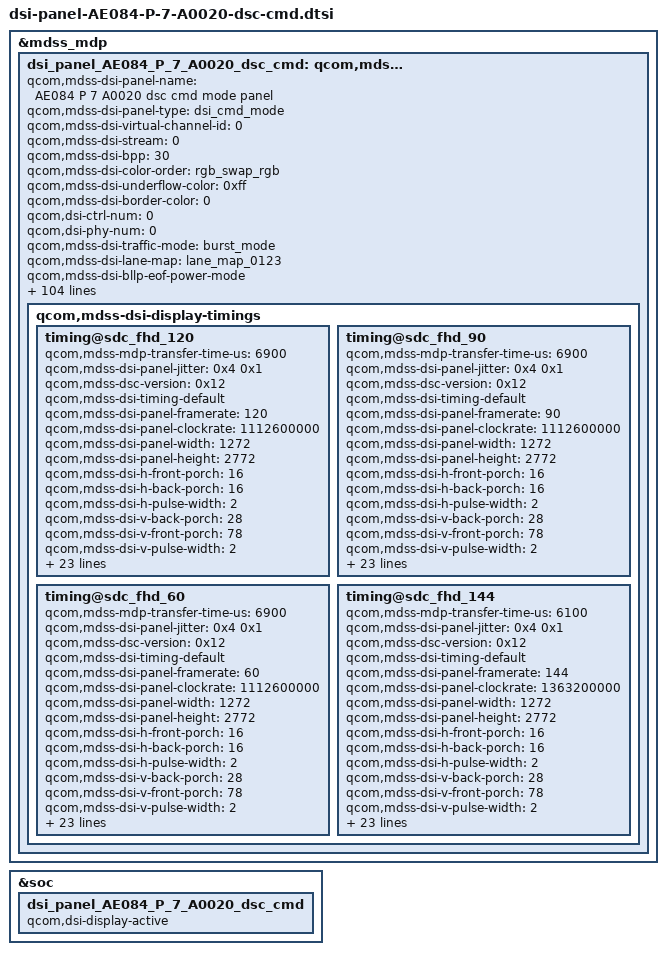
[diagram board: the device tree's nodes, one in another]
&mdss_mdp {
	dsi_panel_AE084_P_7_A0020_dsc_cmd: qcom,mdss_dsi_panel_AE084_P_7_A0020_dsc_cmd {
		qcom,mdss-dsi-panel-name = "AE084 P 7 A0020 dsc cmd mode panel";
		qcom,mdss-dsi-panel-type = "dsi_cmd_mode";
		qcom,mdss-dsi-virtual-channel-id = <0>;
		qcom,mdss-dsi-stream = <0>;
		qcom,mdss-dsi-bpp = <30>;
		qcom,mdss-dsi-color-order = "rgb_swap_rgb";
		qcom,mdss-dsi-underflow-color = <0xff>;
		qcom,mdss-dsi-border-color = <0>;
		qcom,dsi-ctrl-num = <0>;
		qcom,dsi-phy-num = <0>;
		qcom,mdss-dsi-traffic-mode = "burst_mode";
		qcom,mdss-dsi-lane-map = "lane_map_0123";
		qcom,mdss-dsi-bllp-eof-power-mode;
		qcom,mdss-dsi-bllp-power-mode;
		qcom,mdss-dsi-lane-0-state;
		qcom,mdss-dsi-lane-1-state;
		qcom,mdss-dsi-lane-2-state;
		qcom,mdss-dsi-lane-3-state;
		qcom,mdss-dsi-dma-trigger = "trigger_sw";
		qcom,mdss-dsi-dma-schedule-line = <1>;
		qcom,mdss-dsi-dma-schedule-window = <10>;
		qcom,mdss-dsi-mdp-trigger = "none";
		qcom,mdss-dsi-reset-sequence = <1 2>, <0 5>, <1 25>;
		qcom,mdss-dsi-te-pin-select = <1>;
		qcom,mdss-dsi-te-dcs-command = <1>;
		qcom,mdss-pan-physical-width-dimension = <71>;
		qcom,mdss-pan-physical-height-dimension = <157>;
		qcom,mdss-dsi-init-delay-us = <1000>;
		qcom,mdss-dsi-te-check-enable;
		qcom,mdss-dsi-te-using-te-pin;
		qcom,mdss-dsi-lp11-init;
		qcom,mdss-dsi-wr-mem-start = <0x2c>;
		qcom,mdss-dsi-wr-mem-continue = <0x3c>;
		qcom,mdss-dsi-panel-jitter = <0x4 0x1>;
		qcom,mdss-bl-high2bit;
  		/* HDR Setting */
		qcom,mdss-dsi-panel-hdr-enabled;
		qcom,mdss-dsi-panel-hdr-color-primaries = <15635 16450 34000 16000 13250 34500 7500 3000>;
		//update for [MPC15]android.mediapc.cts.PerformanceClassTest#testDisplayHdr pass
		//qcom,mdss-dsi-panel-peak-brightness = <5400000>;
		qcom,mdss-dsi-panel-peak-brightness = <20000000>;
		qcom,mdss-dsi-panel-average-brightness = <2000000>;
		qcom,mdss-dsi-panel-blackness-level = <4000>;


		qcom,dynamic-mode-switch-enabled;
		qcom,dynamic-mode-switch-type = "dynamic-resolution-switch-immediate";
		qcom,mdss-dsi-display-timings {
			timing@sdc_fhd_120 {
				#include "dsi-panel-AE084-P-7-A0020-common.dtsi"
				qcom,mdss-mdp-transfer-time-us = <6900>;
				qcom,mdss-dsi-panel-jitter = <0x4 0x1>;
				qcom,mdss-dsc-version = <0x12>;
				qcom,mdss-dsi-timing-default;
				qcom,mdss-dsi-panel-framerate = <120>;
				qcom,mdss-dsi-panel-clockrate = <1112600000>;
				qcom,mdss-dsi-panel-width = <1272>;
				qcom,mdss-dsi-panel-height = <2772>;

				qcom,mdss-dsi-h-front-porch = <16>;
				qcom,mdss-dsi-h-back-porch = <16>;
				qcom,mdss-dsi-h-pulse-width = <2>;
				qcom,mdss-dsi-v-back-porch = <28>;
				qcom,mdss-dsi-v-front-porch = <78>;
				qcom,mdss-dsi-v-pulse-width = <2>;
				qcom,mdss-dsi-h-sync-pulse = <0>;

				oplus,ofp-need-to-sync-data-in-aod-unlocking;
				oplus,ofp-aod-off-insert-black-frame = <1>;
				oplus,ofp-aod-off-black-frame-total-time = <42>;
				oplus,ofp-need-to-separate-backlight;
				oplus,ofp-backlight-on-period = <1>;

				qcom,mdss-dsi-timing-switch-command = [
					39 00 00 40 00 00 04 FF 5A A5 00
					15 00 00 40 00 00 02 60 00
					39 00 00 40 00 00 04 FF 5A A5 2D
					39 00 00 40 00 00 03 83 00 00
					15 00 00 40 00 00 02 F2 00
				];
				qcom,mdss-dsi-on-command = [
					39 00 00 40 00 00 04 FF 5A A5 20
					15 00 00 40 00 00 02 C8 00
					15 00 00 40 00 00 02 C7 00
					15 00 00 40 00 00 02 BF 17
					39 00 00 40 00 00 04 FF 5A A5 00
					39 00 00 40 00 00 05 94 00 D0 00 00
					39 00 00 40 00 00 04 FF 5A A5 1F
					39 00 00 40 00 00 03 82 00 20
					15 00 00 40 00 00 02 87 09
					15 00 00 40 00 00 02 88 34
					39 00 00 40 00 00 05 89 41 00 C4 01
					39 00 00 40 00 00 03 8A 8C 14
					39 00 00 40 00 00 05 8C 80 07 00 40
					15 00 00 40 00 00 02 8E 10
					15 00 00 40 00 00 02 95 00
					39 00 00 40 00 00 05 96 15 35 55 00
					39 00 00 40 00 00 06 97 11 33 22 01 09
					39 00 00 40 00 00 19 83 00 0B 0A 0C 02 FF FF FF 0C 02 FF FF 00 FF 00 0B 00 FF FF FF FF FF FF FF
					39 00 00 40 00 00 19 8F 03 2C 8C 19 07 00 00 00 19 07 00 00 00 00 02 2C 02 00 00 00 00 00 00 00
					39 00 00 40 00 00 09 85 00 0B 0A FF FF FF FF FF
					39 00 00 40 00 00 09 91 03 2C 24 00 00 00 00 00
					39 00 00 40 00 00 04 FF 5A A5 29
					39 00 00 40 00 00 09 82 78 30 2E 2E 2C 2C 2A 2A
					39 00 00 40 00 00 09 83 28 28 26 26 24 24 22 22
					39 00 00 40 00 00 09 84 20 20 1E 1E 1C 1C 18 18
					39 00 00 40 00 00 07 85 18 18 18 18 18 18
					39 00 00 40 00 00 04 FF 5A A5 00

					39 00 00 40 00 00 04 FF 5A A5 08
					15 00 00 40 00 00 02 C8 62
					39 00 00 40 00 00 04 FF 5A A5 07
					15 00 00 40 00 00 02 8A 01
					39 00 00 40 00 00 03 8B 21 E0 // PPS Table
					39 00 00 40 00 00 64 81 00 00 00 00 00 12 00 00 AB 30 80 0A D4 04 F8 00 16 02 7C 02 7C 02 00 02 59 00 20 02 2E 00 08 00 0D 04 F4 03 ED 18 00 10 F0 07 10 20 00 06 0F 0F 33 0E 1C 2A 38 46 54 62 69 70 77 79 7B 7D 7E 02 02 22 00 2A 40 2A BE 3A FC 3A FA 3A F8 3B 38 3B 78 3B B6 4B B6 4B F4 4B F4 6C 34 84 74 00 00 00 00 00 00
					39 00 00 40 00 00 04 FF 5A A5 00

					39 00 00 40 00 00 04 FF 5A A5 21
					15 00 00 40 00 00 02 A4 18 // Flash reload
					39 00 00 40 00 00 04 FF 5A A5 01
					15 00 00 40 00 00 02 FB 08 // Multi TE
					39 00 00 40 00 00 04 FF 5A A5 06
					15 00 00 40 00 00 02 A0 00 // ESD fixed
					15 00 00 40 00 00 02 C6 01 // 1 bit ESD check
					39 00 00 40 00 00 04 FF 5A A5 08
					15 00 00 40 00 00 02 D2 05
					15 00 00 40 00 00 02 D3 01
					39 00 00 40 00 00 09 ED FF FF FF F7 FF CF 45 FF
					39 00 00 40 00 00 09 EE FF FD C1 F8 21 00 80 50
					39 00 00 40 00 00 04 FF 5A A5 2F
					15 00 00 40 00 00 02 99 80
					39 00 00 40 00 00 04 FF 5A A5 1F
					15 00 00 40 00 00 02 B2 F0
					39 00 00 40 00 00 04 FF 5A A5 6E
					39 00 00 40 00 00 05 C8 66 C4 66 D9
					39 00 00 40 00 00 05 C9 66 A8 66 B3
					39 00 00 40 00 00 05 CA 67 66 66 BB
					39 00 00 40 00 00 05 CB 66 82 66 8D
					39 00 00 40 00 00 05 CC 66 95 67 6F
					39 00 00 40 00 00 05 CD 67 76 67 71
					39 00 00 40 00 00 05 CE 67 4B 67 5A
					39 00 00 40 00 00 05 CF 67 3F 67 0E
					39 00 00 40 00 00 05 D0 67 7B 67 7F
					39 00 00 40 00 00 05 D1 67 76 67 6A
					39 00 00 40 00 00 05 D2 67 66 67 61
					39 00 00 40 00 00 05 D3 67 65 66 90
					39 00 00 40 00 00 05 D4 66 97 66 8B
					39 00 00 40 00 00 05 D5 66 82 66 86
					39 00 00 40 00 00 05 D6 66 BD 66 B1
					39 00 00 40 00 00 05 D7 66 A8 66 AC
					39 00 00 40 00 00 04 FF 5A A5 6B
					39 00 00 40 00 00 05 9B 0C DF 21 F5
					39 00 00 40 00 00 05 9C 58 D8 23 A4
					39 00 00 40 00 00 05 9D 6E E1 21 E7
					39 00 00 40 00 00 05 9E 77 04 2C C2
					39 00 00 40 00 00 05 9F E1 51 1A EA
					39 00 00 40 00 00 05 A0 A4 33 28 29
					39 00 00 40 00 00 05 BF 0C DF 21 F5
					39 00 00 40 00 00 05 C0 58 D8 23 A4
					39 00 00 40 00 00 05 C1 6E E1 21 E7
					39 00 00 40 00 00 05 C2 77 04 2C C2
					39 00 00 40 00 00 05 C3 E1 51 1A EA
					39 00 00 40 00 00 05 C4 A4 33 28 29
					39 00 00 40 00 00 04 FF 5A A5 6C
					39 00 00 40 00 00 05 B3 0D DC 22 DE
					39 00 00 40 00 00 05 B4 48 D9 23 B4
					39 00 00 40 00 00 05 B5 5E EE 2C C0
					39 00 00 40 00 00 05 B6 26 14 2F E9
					39 00 00 40 00 00 05 B7 B2 31 1C ED
					39 00 00 40 00 00 05 B8 E5 50 2F 4B
					39 00 00 40 00 00 05 D7 0D DC 22 DE
					39 00 00 40 00 00 05 D8 48 D9 23 B4
					39 00 00 40 00 00 05 D9 5E EE 2C C0
					39 00 00 40 00 00 05 DA 26 14 2F E9
					39 00 00 40 00 00 05 DB B2 31 1C ED
					39 00 00 40 00 00 05 DC E5 50 2F 4B
					39 00 00 40 00 00 04 FF 5A A5 2F
					15 00 00 40 00 00 02 99 00
					39 00 00 40 00 00 04 FF 5A A5 00
					15 00 00 40 00 00 02 5E 01
					15 00 00 40 00 00 02 60 00
					15 00 00 40 00 00 02 61 07
					15 00 00 40 00 00 02 6D 01
					15 00 00 40 00 00 02 35 00
					15 00 00 40 00 00 02 53 20
					39 00 00 40 00 00 05 51 07 4D 03 DD // p1 p2 normal DBV p3 p4 AOD DBV
					// switch 120HZ
					39 00 00 40 00 00 04 FF 5A A5 00
					15 00 00 40 00 00 02 60 00
					39 00 00 40 00 00 04 FF 5A A5 2D
					39 00 00 40 00 00 03 83 00 00
					15 00 00 40 00 00 02 F2 00
					39 00 00 00 02 00 04 FF 5A A5 00
					//Light On
					15 00 00 00 78 00 02 11 00
					15 00 00 00 14 00 02 29 00
				];
				/* PWM */
				qcom,mdss-dsi-pwm-switch-mode0-command = [
					39 00 00 40 00 00 04 FF 5A A5 00
					15 00 00 40 00 00 02 60 01
					39 00 00 40 00 00 04 FF 5A A5 2D
					15 00 00 40 00 00 02 F2 00
					39 00 00 40 00 00 04 FF 5A A5 23
					15 00 00 40 00 00 02 CA 00
					15 00 00 40 00 00 02 CE 00
					39 00 00 40 00 00 04 FF 5A A5 24
					15 00 00 40 00 00 02 8D 02
					15 00 00 40 00 00 02 8E 60
					15 00 00 40 00 00 02 8F 43
					15 00 00 40 00 00 02 90 70
					39 00 00 40 00 00 04 FF 5A A5 01
					39 00 00 40 00 00 07 80 0C 00 00 00 10 33
					39 00 00 40 00 00 04 FF 5A A5 0A
					39 00 00 40 00 00 05 D8 00 07 35 80
					39 00 00 40 00 00 04 FF 5A A5 0B
					39 00 00 40 00 00 04 E9 00 00 2D
					39 00 00 40 00 00 04 FF 5A A5 51
					39 00 00 40 00 00 07 A0 CA CA CA CA 22 22
					39 00 00 40 00 00 07 A1 CA CA CA CA 22 22
					39 00 00 40 00 00 07 A2 CA CA CA CA 22 22
					39 00 00 40 00 00 07 A3 CA CA CA CA 22 22
					39 00 00 40 00 00 07 A4 CA CA CA CA 22 22
					39 00 00 40 00 00 07 A5 CA CA CA CA 22 22
					39 00 00 40 00 00 07 A6 CA CA CA CA 22 22
					39 00 00 40 00 00 07 A7 CA CA 00 00 22 00
					39 00 00 40 00 00 04 FF 5A A5 52
					39 00 00 40 00 00 07 80 2C 78 73 73 01 00
					39 00 00 40 00 00 07 81 6E 6E 69 69 00 00
					39 00 00 40 00 00 07 82 64 64 5F 5F 00 00
					39 00 00 40 00 00 07 83 5A 5A 55 55 00 00
					39 00 00 40 00 00 07 84 50 50 4B 4B 00 00
					39 00 00 00 00 00 07 85 46 46 46 46 00 00
				];
				qcom,mdss-dsi-pwm-switch-mode2-command = [
					39 00 00 40 00 00 04 FF 5A A5 00
					15 00 00 40 00 00 02 60 00
					39 00 00 40 00 00 04 FF 5A A5 2D
					15 00 00 40 00 00 02 F2 00
					39 00 00 40 00 00 04 FF 5A A5 23
					15 00 00 40 00 00 02 CA 04
					15 00 00 40 00 00 02 CE 01
					39 00 00 40 00 00 04 FF 5A A5 24
					15 00 00 40 00 00 02 8D 01
					15 00 00 40 00 00 02 8E 30
					15 00 00 40 00 00 02 8F 21
					15 00 00 40 00 00 02 90 30
					39 00 00 40 00 00 04 FF 5A A5 01
					39 00 00 40 00 00 07 80 0C 00 00 00 10 27
					39 00 00 40 00 00 04 FF 5A A5 0A
					39 00 00 40 00 00 05 D8 00 07 29 80
					39 00 00 40 00 00 04 FF 5A A5 0B
					39 00 00 40 00 00 04 E9 00 00 21
					39 00 00 40 00 00 04 FF 5A A5 51
					39 00 00 40 00 00 07 A0 CB CB CB CB 22 22
					39 00 00 40 00 00 07 A1 CB CB CB CB 22 22
					39 00 00 40 00 00 07 A2 CB CB CB CB 22 22
					39 00 00 40 00 00 07 A3 CB CB CB CB 22 22
					39 00 00 40 00 00 07 A4 CB CB CB CB 22 22
					39 00 00 40 00 00 07 A5 CB CB CB C7 22 22
					39 00 00 40 00 00 07 A6 C7 C3 C3 C3 22 22
					39 00 00 40 00 00 07 A7 C3 C3 00 00 22 00
					39 00 00 40 00 00 04 FF 5A A5 52
					39 00 00 40 00 00 07 80 2D 79 74 74 01 00
					39 00 00 40 00 00 07 81 6F 6F 6A 6A 00 00
					39 00 00 40 00 00 07 82 65 65 60 60 00 00
					39 00 00 40 00 00 07 83 5B 5B 56 56 00 00
					39 00 00 40 00 00 07 84 51 51 4C 4C 00 00
					39 00 00 40 00 00 07 85 47 47 47 46 00 00
					39 00 00 00 00 00 07 86 46 46 46 46 00 00
				];
				qcom,mdss-dsi-timming-switch-pwm-mode2-command = [
					/* 120Hz DC */
					39 00 00 40 00 00 04 FF 5A A5 00
					15 00 00 40 00 00 02 60 01
					39 00 00 40 00 00 04 FF 5A A5 2D
					39 00 00 40 00 00 03 84 00 00
					15 00 00 40 00 00 02 F2 00
					39 00 00 00 00 00 04 FF 5A A5 00
				];
				qcom,mdss-dsi-pwm-switch-mode2-panel-on-command = [
					39 00 00 40 00 00 04 FF 5A A5 00
					15 00 00 40 00 00 02 60 00
					39 00 00 40 00 00 04 FF 5A A5 2D
					15 00 00 40 00 00 02 F2 00
					39 00 00 40 00 00 04 FF 5A A5 23
					15 00 00 40 00 00 02 CA 04
					15 00 00 40 00 00 02 CE 01
					39 00 00 40 00 00 04 FF 5A A5 24
					15 00 00 40 00 00 02 8D 01
					15 00 00 40 00 00 02 8E 30
					15 00 00 40 00 00 02 8F 21
					15 00 00 40 00 00 02 90 30
					39 00 00 40 00 00 04 FF 5A A5 01
					39 00 00 40 00 00 07 80 0C 00 00 00 10 27
					39 00 00 40 00 00 04 FF 5A A5 0A
					39 00 00 40 00 00 05 D8 00 07 29 80
					39 00 00 40 00 00 04 FF 5A A5 0B
					39 00 00 40 00 00 04 E9 00 00 21
					39 00 00 40 00 00 04 FF 5A A5 51
					39 00 00 40 00 00 07 A0 CB CB CB CB 22 22
					39 00 00 40 00 00 07 A1 CB CB CB CB 22 22
					39 00 00 40 00 00 07 A2 CB CB CB CB 22 22
					39 00 00 40 00 00 07 A3 CB CB CB CB 22 22
					39 00 00 40 00 00 07 A4 CB CB CB CB 22 22
					39 00 00 40 00 00 07 A5 CB CB CB C7 22 22
					39 00 00 40 00 00 07 A6 C7 C3 C3 C3 22 22
					39 00 00 40 00 00 07 A7 C3 C3 00 00 22 00
					39 00 00 40 00 00 04 FF 5A A5 52
					39 00 00 40 00 00 07 80 2D 79 74 74 01 00
					39 00 00 40 00 00 07 81 6F 6F 6A 6A 00 00
					39 00 00 40 00 00 07 82 65 65 60 60 00 00
					39 00 00 40 00 00 07 83 5B 5B 56 56 00 00
					39 00 00 40 00 00 07 84 51 51 4C 4C 00 00
					39 00 00 40 00 00 07 85 47 47 47 46 00 00
					39 00 00 00 00 00 07 86 46 46 46 46 00 00
				];
			};
			timing@sdc_fhd_90 {
				#include "dsi-panel-AE084-P-7-A0020-common.dtsi"
				qcom,mdss-mdp-transfer-time-us = <6900>;
				qcom,mdss-dsi-panel-jitter = <0x4 0x1>;
				qcom,mdss-dsc-version = <0x12>;
				qcom,mdss-dsi-timing-default;
				qcom,mdss-dsi-panel-framerate = <90>;
				qcom,mdss-dsi-panel-clockrate = <1112600000>;
				qcom,mdss-dsi-panel-width = <1272>;
				qcom,mdss-dsi-panel-height = <2772>;

				qcom,mdss-dsi-h-front-porch = <16>;
				qcom,mdss-dsi-h-back-porch = <16>;
				qcom,mdss-dsi-h-pulse-width = <2>;
				qcom,mdss-dsi-v-back-porch = <28>;
				qcom,mdss-dsi-v-front-porch = <78>;
				qcom,mdss-dsi-v-pulse-width = <2>;
				qcom,mdss-dsi-h-sync-pulse = <0>;

				oplus,ofp-need-to-sync-data-in-aod-unlocking;
				oplus,ofp-aod-off-insert-black-frame = <1>;
				oplus,ofp-aod-off-black-frame-total-time = <42>;
				oplus,ofp-need-to-separate-backlight;
				oplus,ofp-backlight-on-period = <1>;

				qcom,mdss-dsi-timing-switch-command = [
					39 00 00 40 00 00 04 FF 5A A5 00
					15 00 00 40 00 00 02 60 02 //90hz 3 pulse
					39 00 00 40 00 00 04 FF 5A A5 2D
					39 00 00 40 00 00 03 85 00 00
					39 00 00 00 00 00 04 FF 5A A5 00
				];
				qcom,mdss-dsi-on-command = [
					39 00 00 40 00 00 04 FF 5A A5 20
					15 00 00 40 00 00 02 C8 00
					15 00 00 40 00 00 02 C7 00
					15 00 00 40 00 00 02 BF 17
					39 00 00 40 00 00 04 FF 5A A5 00
					39 00 00 40 00 00 05 94 00 D0 00 00
					39 00 00 40 00 00 04 FF 5A A5 1F
					39 00 00 40 00 00 03 82 00 20
					15 00 00 40 00 00 02 87 09
					15 00 00 40 00 00 02 88 34
					39 00 00 40 00 00 05 89 41 00 C4 01
					39 00 00 40 00 00 03 8A 8C 14
					39 00 00 40 00 00 05 8C 80 07 00 40
					15 00 00 40 00 00 02 8E 10
					15 00 00 40 00 00 02 95 00
					39 00 00 40 00 00 05 96 15 35 55 00
					39 00 00 40 00 00 06 97 11 33 22 01 09
					39 00 00 40 00 00 19 83 00 0B 0A 0C 02 FF FF FF 0C 02 FF FF 00 FF 00 0B 00 FF FF FF FF FF FF FF
					39 00 00 40 00 00 19 8F 03 2C 8C 19 07 00 00 00 19 07 00 00 00 00 02 2C 02 00 00 00 00 00 00 00
					39 00 00 40 00 00 09 85 00 0B 0A FF FF FF FF FF
					39 00 00 40 00 00 09 91 03 2C 24 00 00 00 00 00
					39 00 00 40 00 00 04 FF 5A A5 29
					39 00 00 40 00 00 09 82 78 30 2E 2E 2C 2C 2A 2A
					39 00 00 40 00 00 09 83 28 28 26 26 24 24 22 22
					39 00 00 40 00 00 09 84 20 20 1E 1E 1C 1C 18 18
					39 00 00 40 00 00 07 85 18 18 18 18 18 18
					39 00 00 40 00 00 04 FF 5A A5 00

					39 00 00 40 00 00 04 FF 5A A5 08
					15 00 00 40 00 00 02 C8 62
					39 00 00 40 00 00 04 FF 5A A5 07
					15 00 00 40 00 00 02 8A 01
					39 00 00 40 00 00 03 8B 21 E0 // PPS Table
					39 00 00 40 00 00 64 81 00 00 00 00 00 12 00 00 AB 30 80 0A D4 04 F8 00 16 02 7C 02 7C 02 00 02 59 00 20 02 2E 00 08 00 0D 04 F4 03 ED 18 00 10 F0 07 10 20 00 06 0F 0F 33 0E 1C 2A 38 46 54 62 69 70 77 79 7B 7D 7E 02 02 22 00 2A 40 2A BE 3A FC 3A FA 3A F8 3B 38 3B 78 3B B6 4B B6 4B F4 4B F4 6C 34 84 74 00 00 00 00 00 00
					39 00 00 40 00 00 04 FF 5A A5 00

					39 00 00 40 00 00 04 FF 5A A5 21
					15 00 00 40 00 00 02 A4 18 // Flash reload
					39 00 00 40 00 00 04 FF 5A A5 01
					15 00 00 40 00 00 02 FB 08 // Multi TE
					39 00 00 40 00 00 04 FF 5A A5 06
					15 00 00 40 00 00 02 A0 00 // ESD fixed
					15 00 00 40 00 00 02 C6 01 // 1 bit ESD check
					39 00 00 40 00 00 04 FF 5A A5 08
					15 00 00 40 00 00 02 D2 05
					15 00 00 40 00 00 02 D3 01
					39 00 00 40 00 00 09 ED FF FF FF F7 FF CF 45 FF
					39 00 00 40 00 00 09 EE FF FD C1 F8 21 00 80 50
					39 00 00 40 00 00 04 FF 5A A5 2F
					15 00 00 40 00 00 02 99 80
					39 00 00 40 00 00 04 FF 5A A5 1F
					15 00 00 40 00 00 02 B2 F0
					39 00 00 40 00 00 04 FF 5A A5 6E
					39 00 00 40 00 00 05 C8 66 C4 66 D9
					39 00 00 40 00 00 05 C9 66 A8 66 B3
					39 00 00 40 00 00 05 CA 67 66 66 BB
					39 00 00 40 00 00 05 CB 66 82 66 8D
					39 00 00 40 00 00 05 CC 66 95 67 6F
					39 00 00 40 00 00 05 CD 67 76 67 71
					39 00 00 40 00 00 05 CE 67 4B 67 5A
					39 00 00 40 00 00 05 CF 67 3F 67 0E
					39 00 00 40 00 00 05 D0 67 7B 67 7F
					39 00 00 40 00 00 05 D1 67 76 67 6A
					39 00 00 40 00 00 05 D2 67 66 67 61
					39 00 00 40 00 00 05 D3 67 65 66 90
					39 00 00 40 00 00 05 D4 66 97 66 8B
					39 00 00 40 00 00 05 D5 66 82 66 86
					39 00 00 40 00 00 05 D6 66 BD 66 B1
					39 00 00 40 00 00 05 D7 66 A8 66 AC
					39 00 00 40 00 00 04 FF 5A A5 6B
					39 00 00 40 00 00 05 9B 0C DF 21 F5
					39 00 00 40 00 00 05 9C 58 D8 23 A4
					39 00 00 40 00 00 05 9D 6E E1 21 E7
					39 00 00 40 00 00 05 9E 77 04 2C C2
					39 00 00 40 00 00 05 9F E1 51 1A EA
					39 00 00 40 00 00 05 A0 A4 33 28 29
					39 00 00 40 00 00 05 BF 0C DF 21 F5
					39 00 00 40 00 00 05 C0 58 D8 23 A4
					39 00 00 40 00 00 05 C1 6E E1 21 E7
					39 00 00 40 00 00 05 C2 77 04 2C C2
					39 00 00 40 00 00 05 C3 E1 51 1A EA
					39 00 00 40 00 00 05 C4 A4 33 28 29
					39 00 00 40 00 00 04 FF 5A A5 6C
					39 00 00 40 00 00 05 B3 0D DC 22 DE
					39 00 00 40 00 00 05 B4 48 D9 23 B4
					39 00 00 40 00 00 05 B5 5E EE 2C C0
					39 00 00 40 00 00 05 B6 26 14 2F E9
					39 00 00 40 00 00 05 B7 B2 31 1C ED
					39 00 00 40 00 00 05 B8 E5 50 2F 4B
					39 00 00 40 00 00 05 D7 0D DC 22 DE
					39 00 00 40 00 00 05 D8 48 D9 23 B4
					39 00 00 40 00 00 05 D9 5E EE 2C C0
					39 00 00 40 00 00 05 DA 26 14 2F E9
					39 00 00 40 00 00 05 DB B2 31 1C ED
					39 00 00 40 00 00 05 DC E5 50 2F 4B
					39 00 00 40 00 00 04 FF 5A A5 2F
					15 00 00 40 00 00 02 99 00
					39 00 00 40 00 00 04 FF 5A A5 00
					15 00 00 40 00 00 02 5E 01
					15 00 00 40 00 00 02 60 00
					15 00 00 40 00 00 02 61 07
					15 00 00 40 00 00 02 6D 01
					15 00 00 40 00 00 02 35 00
					15 00 00 40 00 00 02 53 20
					39 00 00 40 00 00 05 51 07 4D 03 DD // p1 p2 normal DBV p3 p4 AOD DBV
					// switch 90HZ
					39 00 00 40 00 00 04 FF 5A A5 00
					15 00 00 40 00 00 02 60 02 //90hz 3 pulse
					39 00 00 40 00 00 04 FF 5A A5 2D
					39 00 00 40 00 00 03 85 00 00
					39 00 00 00 02 00 04 FF 5A A5 00
					//Light On
					15 00 00 00 78 00 02 11 00
					15 00 00 00 14 00 02 29 00
				];
				/* PWM */
				qcom,mdss-dsi-pwm-switch-mode0-command = [
					39 00 00 40 00 00 04 FF 5A A5 00
					15 00 00 40 00 00 02 60 03
					39 00 00 40 00 00 04 FF 5A A5 23
					15 00 00 40 00 00 02 CA 00
					15 00 00 40 00 00 02 CE 00
					39 00 00 40 00 00 04 FF 5A A5 24
					15 00 00 40 00 00 02 8D 02
					15 00 00 40 00 00 02 8E 60
					15 00 00 40 00 00 02 8F 43
					15 00 00 40 00 00 02 90 70
					39 00 00 40 00 00 04 FF 5A A5 01
					39 00 00 40 00 00 07 80 0C 00 00 00 10 33
					39 00 00 40 00 00 04 FF 5A A5 0A
					39 00 00 40 00 00 05 D8 00 07 35 80
					39 00 00 40 00 00 04 FF 5A A5 0B
					39 00 00 40 00 00 04 E9 00 00 2D
					39 00 00 40 00 00 04 FF 5A A5 51
					39 00 00 40 00 00 07 A0 CA CA CA CA 22 22
					39 00 00 40 00 00 07 A1 CA CA CA CA 22 22
					39 00 00 40 00 00 07 A2 CA CA CA CA 22 22
					39 00 00 40 00 00 07 A3 CA CA CA CA 22 22
					39 00 00 40 00 00 07 A4 CA CA CA CA 22 22
					39 00 00 40 00 00 07 A5 CA CA CA CA 22 22
					39 00 00 40 00 00 07 A6 CA CA CA CA 22 22
					39 00 00 40 00 00 07 A7 CA CA 00 00 22 00
					39 00 00 40 00 00 04 FF 5A A5 52
					39 00 00 40 00 00 07 80 2C 78 73 73 01 00
					39 00 00 40 00 00 07 81 6E 6E 69 69 00 00
					39 00 00 40 00 00 07 82 64 64 5F 5F 00 00
					39 00 00 40 00 00 07 83 5A 5A 55 55 00 00
					39 00 00 40 00 00 07 84 50 50 4B 4B 00 00
					39 00 00 00 00 00 07 85 46 46 46 46 00 00
				];
				qcom,mdss-dsi-pwm-switch-mode2-command = [
					39 00 00 40 00 00 04 FF 5A A5 00
					15 00 00 40 00 00 02 60 02
					39 00 00 40 00 00 04 FF 5A A5 23
					15 00 00 40 00 00 02 CA 04
					15 00 00 40 00 00 02 CE 01
					39 00 00 40 00 00 04 FF 5A A5 24
					15 00 00 40 00 00 02 8D 01
					15 00 00 40 00 00 02 8E 30
					15 00 00 40 00 00 02 8F 21
					15 00 00 40 00 00 02 90 30
					39 00 00 40 00 00 04 FF 5A A5 01
					39 00 00 40 00 00 07 80 0C 00 00 00 10 27
					39 00 00 40 00 00 04 FF 5A A5 0A
					39 00 00 40 00 00 05 D8 00 07 29 80
					39 00 00 40 00 00 04 FF 5A A5 0B
					39 00 00 40 00 00 04 E9 00 00 21
					39 00 00 40 00 00 04 FF 5A A5 51
					39 00 00 40 00 00 07 A0 CB CB CB CB 22 22
					39 00 00 40 00 00 07 A1 CB CB CB CB 22 22
					39 00 00 40 00 00 07 A2 CB CB CB CB 22 22
					39 00 00 40 00 00 07 A3 CB CB CB CB 22 22
					39 00 00 40 00 00 07 A4 CB CB CB CB 22 22
					39 00 00 40 00 00 07 A5 CB CB CB C7 22 22
					39 00 00 40 00 00 07 A6 C7 C3 C3 C3 22 22
					39 00 00 40 00 00 07 A7 C3 C3 00 00 22 00
					39 00 00 40 00 00 04 FF 5A A5 52
					39 00 00 40 00 00 07 80 2D 79 74 74 01 00
					39 00 00 40 00 00 07 81 6F 6F 6A 6A 00 00
					39 00 00 40 00 00 07 82 65 65 60 60 00 00
					39 00 00 40 00 00 07 83 5B 5B 56 56 00 00
					39 00 00 40 00 00 07 84 51 51 4C 4C 00 00
					39 00 00 00 00 00 07 85 47 47 47 46 00 00
				];
				qcom,mdss-dsi-timming-switch-pwm-mode2-command = [
					/* 90Hz DC */
					39 00 00 40 00 00 04 FF 5A A5 00
					15 00 00 40 00 00 02 60 03
					39 00 00 40 00 00 04 FF 5A A5 2D
					39 00 00 40 00 00 03 86 00 00
					15 00 00 40 00 00 02 F2 00
					39 00 00 00 00 00 04 FF 5A A5 00
				];
				qcom,mdss-dsi-pwm-switch-mode2-panel-on-command = [
					39 00 00 40 00 00 04 FF 5A A5 00
					15 00 00 40 00 00 02 60 02
					39 00 00 40 00 00 04 FF 5A A5 23
					15 00 00 40 00 00 02 CA 04
					15 00 00 40 00 00 02 CE 01
					39 00 00 40 00 00 04 FF 5A A5 24
					15 00 00 40 00 00 02 8D 01
					15 00 00 40 00 00 02 8E 30
					15 00 00 40 00 00 02 8F 21
					15 00 00 40 00 00 02 90 30
					39 00 00 40 00 00 04 FF 5A A5 01
					39 00 00 40 00 00 07 80 0C 00 00 00 10 27
					39 00 00 40 00 00 04 FF 5A A5 0A
					39 00 00 40 00 00 05 D8 00 07 29 80
					39 00 00 40 00 00 04 FF 5A A5 0B
					39 00 00 40 00 00 04 E9 00 00 21
					39 00 00 40 00 00 04 FF 5A A5 51
					39 00 00 40 00 00 07 A0 CB CB CB CB 22 22
					39 00 00 40 00 00 07 A1 CB CB CB CB 22 22
					39 00 00 40 00 00 07 A2 CB CB CB CB 22 22
					39 00 00 40 00 00 07 A3 CB CB CB CB 22 22
					39 00 00 40 00 00 07 A4 CB CB CB CB 22 22
					39 00 00 40 00 00 07 A5 CB CB CB C7 22 22
					39 00 00 40 00 00 07 A6 C7 C3 C3 C3 22 22
					39 00 00 40 00 00 07 A7 C3 C3 00 00 22 00
					39 00 00 40 00 00 04 FF 5A A5 52
					39 00 00 40 00 00 07 80 2D 79 74 74 01 00
					39 00 00 40 00 00 07 81 6F 6F 6A 6A 00 00
					39 00 00 40 00 00 07 82 65 65 60 60 00 00
					39 00 00 40 00 00 07 83 5B 5B 56 56 00 00
					39 00 00 40 00 00 07 84 51 51 4C 4C 00 00
					39 00 00 00 00 00 07 85 47 47 47 46 00 00
				];
			};
			timing@sdc_fhd_60 {
				#include "dsi-panel-AE084-P-7-A0020-common.dtsi"
				qcom,mdss-mdp-transfer-time-us = <6900>;
				qcom,mdss-dsi-panel-jitter = <0x4 0x1>;
				qcom,mdss-dsc-version = <0x12>;
				qcom,mdss-dsi-timing-default;
				qcom,mdss-dsi-panel-framerate = <60>;
				qcom,mdss-dsi-panel-clockrate = <1112600000>;
				qcom,mdss-dsi-panel-width = <1272>;
				qcom,mdss-dsi-panel-height = <2772>;

				qcom,mdss-dsi-h-front-porch = <16>;
				qcom,mdss-dsi-h-back-porch = <16>;
				qcom,mdss-dsi-h-pulse-width = <2>;
				qcom,mdss-dsi-v-back-porch = <28>;
				qcom,mdss-dsi-v-front-porch = <78>;
				qcom,mdss-dsi-v-pulse-width = <2>;
				qcom,mdss-dsi-h-sync-pulse = <0>;

				oplus,ofp-need-to-sync-data-in-aod-unlocking;
				oplus,ofp-aod-off-insert-black-frame = <1>;
				oplus,ofp-aod-off-black-frame-total-time = <42>;
				oplus,ofp-need-to-separate-backlight;
				oplus,ofp-backlight-on-period = <1>;

				qcom,mdss-dsi-timing-switch-command = [
					39 00 00 40 00 00 04 FF 5A A5 00
					15 00 00 40 00 00 02 60 00
					39 00 00 40 00 00 04 FF 5A A5 2D
					39 00 00 40 00 00 03 83 01 00
					15 00 00 40 00 00 02 F2 01
					39 00 00 00 00 00 04 FF 5A A5 00
				];
				qcom,mdss-dsi-on-command = [
					39 00 00 40 00 00 04 FF 5A A5 20
					15 00 00 40 00 00 02 C8 00
					15 00 00 40 00 00 02 C7 00
					15 00 00 40 00 00 02 BF 17
					39 00 00 40 00 00 04 FF 5A A5 00
					39 00 00 40 00 00 05 94 00 D0 00 00
					39 00 00 40 00 00 04 FF 5A A5 1F
					39 00 00 40 00 00 03 82 00 20
					15 00 00 40 00 00 02 87 09
					15 00 00 40 00 00 02 88 34
					39 00 00 40 00 00 05 89 41 00 C4 01
					39 00 00 40 00 00 03 8A 8C 14
					39 00 00 40 00 00 05 8C 80 07 00 40
					15 00 00 40 00 00 02 8E 10
					15 00 00 40 00 00 02 95 00
					39 00 00 40 00 00 05 96 15 35 55 00
					39 00 00 40 00 00 06 97 11 33 22 01 09
					39 00 00 40 00 00 19 83 00 0B 0A 0C 02 FF FF FF 0C 02 FF FF 00 FF 00 0B 00 FF FF FF FF FF FF FF
					39 00 00 40 00 00 19 8F 03 2C 8C 19 07 00 00 00 19 07 00 00 00 00 02 2C 02 00 00 00 00 00 00 00
					39 00 00 40 00 00 09 85 00 0B 0A FF FF FF FF FF
					39 00 00 40 00 00 09 91 03 2C 24 00 00 00 00 00
					39 00 00 40 00 00 04 FF 5A A5 29
					39 00 00 40 00 00 09 82 78 30 2E 2E 2C 2C 2A 2A
					39 00 00 40 00 00 09 83 28 28 26 26 24 24 22 22
					39 00 00 40 00 00 09 84 20 20 1E 1E 1C 1C 18 18
					39 00 00 40 00 00 07 85 18 18 18 18 18 18
					39 00 00 40 00 00 04 FF 5A A5 00

					39 00 00 40 00 00 04 FF 5A A5 08
					15 00 00 40 00 00 02 C8 62
					39 00 00 40 00 00 04 FF 5A A5 07
					15 00 00 40 00 00 02 8A 01
					39 00 00 40 00 00 03 8B 21 E0 // PPS Table
					39 00 00 40 00 00 64 81 00 00 00 00 00 12 00 00 AB 30 80 0A D4 04 F8 00 16 02 7C 02 7C 02 00 02 59 00 20 02 2E 00 08 00 0D 04 F4 03 ED 18 00 10 F0 07 10 20 00 06 0F 0F 33 0E 1C 2A 38 46 54 62 69 70 77 79 7B 7D 7E 02 02 22 00 2A 40 2A BE 3A FC 3A FA 3A F8 3B 38 3B 78 3B B6 4B B6 4B F4 4B F4 6C 34 84 74 00 00 00 00 00 00
					39 00 00 40 00 00 04 FF 5A A5 00

					39 00 00 40 00 00 04 FF 5A A5 21
					15 00 00 40 00 00 02 A4 18 // Flash reload
					39 00 00 40 00 00 04 FF 5A A5 01
					15 00 00 40 00 00 02 FB 08 // Multi TE
					39 00 00 40 00 00 04 FF 5A A5 06
					15 00 00 40 00 00 02 A0 00 // ESD fixed
					15 00 00 40 00 00 02 C6 01 // 1 bit ESD check
					39 00 00 40 00 00 04 FF 5A A5 08
					15 00 00 40 00 00 02 D2 05
					15 00 00 40 00 00 02 D3 01
					39 00 00 40 00 00 09 ED FF FF FF F7 FF CF 45 FF
					39 00 00 40 00 00 09 EE FF FD C1 F8 21 00 80 50
					39 00 00 40 00 00 04 FF 5A A5 2F
					15 00 00 40 00 00 02 99 80
					39 00 00 40 00 00 04 FF 5A A5 1F
					15 00 00 40 00 00 02 B2 F0
					39 00 00 40 00 00 04 FF 5A A5 6E
					39 00 00 40 00 00 05 C8 66 C4 66 D9
					39 00 00 40 00 00 05 C9 66 A8 66 B3
					39 00 00 40 00 00 05 CA 67 66 66 BB
					39 00 00 40 00 00 05 CB 66 82 66 8D
					39 00 00 40 00 00 05 CC 66 95 67 6F
					39 00 00 40 00 00 05 CD 67 76 67 71
					39 00 00 40 00 00 05 CE 67 4B 67 5A
					39 00 00 40 00 00 05 CF 67 3F 67 0E
					39 00 00 40 00 00 05 D0 67 7B 67 7F
					39 00 00 40 00 00 05 D1 67 76 67 6A
					39 00 00 40 00 00 05 D2 67 66 67 61
					39 00 00 40 00 00 05 D3 67 65 66 90
					39 00 00 40 00 00 05 D4 66 97 66 8B
					39 00 00 40 00 00 05 D5 66 82 66 86
					39 00 00 40 00 00 05 D6 66 BD 66 B1
					39 00 00 40 00 00 05 D7 66 A8 66 AC
					39 00 00 40 00 00 04 FF 5A A5 6B
					39 00 00 40 00 00 05 9B 0C DF 21 F5
					39 00 00 40 00 00 05 9C 58 D8 23 A4
					39 00 00 40 00 00 05 9D 6E E1 21 E7
					39 00 00 40 00 00 05 9E 77 04 2C C2
					39 00 00 40 00 00 05 9F E1 51 1A EA
					39 00 00 40 00 00 05 A0 A4 33 28 29
					39 00 00 40 00 00 05 BF 0C DF 21 F5
					39 00 00 40 00 00 05 C0 58 D8 23 A4
					39 00 00 40 00 00 05 C1 6E E1 21 E7
					39 00 00 40 00 00 05 C2 77 04 2C C2
					39 00 00 40 00 00 05 C3 E1 51 1A EA
					39 00 00 40 00 00 05 C4 A4 33 28 29
					39 00 00 40 00 00 04 FF 5A A5 6C
					39 00 00 40 00 00 05 B3 0D DC 22 DE
					39 00 00 40 00 00 05 B4 48 D9 23 B4
					39 00 00 40 00 00 05 B5 5E EE 2C C0
					39 00 00 40 00 00 05 B6 26 14 2F E9
					39 00 00 40 00 00 05 B7 B2 31 1C ED
					39 00 00 40 00 00 05 B8 E5 50 2F 4B
					39 00 00 40 00 00 05 D7 0D DC 22 DE
					39 00 00 40 00 00 05 D8 48 D9 23 B4
					39 00 00 40 00 00 05 D9 5E EE 2C C0
					39 00 00 40 00 00 05 DA 26 14 2F E9
					39 00 00 40 00 00 05 DB B2 31 1C ED
					39 00 00 40 00 00 05 DC E5 50 2F 4B
					39 00 00 40 00 00 04 FF 5A A5 2F
					15 00 00 40 00 00 02 99 00
					39 00 00 40 00 00 04 FF 5A A5 00
					15 00 00 40 00 00 02 5E 01
					15 00 00 40 00 00 02 60 00
					15 00 00 40 00 00 02 61 07
					15 00 00 40 00 00 02 6D 01
					15 00 00 40 00 00 02 35 00
					15 00 00 40 00 00 02 53 20
					39 00 00 40 00 00 05 51 07 4D 03 DD // p1 p2 normal DBV p3 p4 AOD DBV
					// switch 60HZ
					39 00 00 40 00 00 04 FF 5A A5 00
					15 00 00 40 00 00 02 60 00
					39 00 00 40 00 00 04 FF 5A A5 2D
					39 00 00 40 00 00 03 83 01 00
					15 00 00 40 00 00 02 F2 00
					39 00 00 00 02 00 04 FF 5A A5 00
					//Light On
					15 00 00 00 78 00 02 11 00
					15 00 00 00 14 00 02 29 00
				];
				/* PWM */
				qcom,mdss-dsi-pwm-switch-mode0-command = [
					39 00 00 40 00 00 04 FF 5A A5 00
					15 00 00 40 00 00 02 60 01
					39 00 00 40 00 00 04 FF 5A A5 2D
					39 00 00 40 00 00 03 84 01 00
					15 00 00 40 00 00 02 F2 01
					39 00 00 40 00 00 04 FF 5A A5 23
					15 00 00 40 00 00 02 CA 00
					15 00 00 40 00 00 02 CE 00
					39 00 00 40 00 00 04 FF 5A A5 24
					15 00 00 40 00 00 02 8D 02
					15 00 00 40 00 00 02 8E 60
					15 00 00 40 00 00 02 8F 43
					15 00 00 40 00 00 02 90 70
					39 00 00 40 00 00 04 FF 5A A5 01
					39 00 00 40 00 00 07 80 0C 00 00 00 10 33
					39 00 00 40 00 00 04 FF 5A A5 0A
					39 00 00 40 00 00 05 D8 00 07 35 80
					39 00 00 40 00 00 04 FF 5A A5 0B
					39 00 00 40 00 00 04 E9 00 00 2D
					39 00 00 40 00 00 04 FF 5A A5 51
					39 00 00 40 00 00 07 A0 CA CA CA CA 22 22
					39 00 00 40 00 00 07 A1 CA CA CA CA 22 22
					39 00 00 40 00 00 07 A2 CA CA CA CA 22 22
					39 00 00 40 00 00 07 A3 CA CA CA CA 22 22
					39 00 00 40 00 00 07 A4 CA CA CA CA 22 22
					39 00 00 40 00 00 07 A5 CA CA CA CA 22 22
					39 00 00 40 00 00 07 A6 CA CA CA CA 22 22
					39 00 00 40 00 00 07 A7 CA CA 00 00 22 00
					39 00 00 40 00 00 04 FF 5A A5 52
					39 00 00 40 00 00 07 80 2C 78 73 73 01 00
					39 00 00 40 00 00 07 81 6E 6E 69 69 00 00
					39 00 00 40 00 00 07 82 64 64 5F 5F 00 00
					39 00 00 40 00 00 07 83 5A 5A 55 55 00 00
					39 00 00 40 00 00 07 84 50 50 4B 4B 00 00
					39 00 00 00 00 00 07 85 46 46 46 46 00 00
				];
				qcom,mdss-dsi-pwm-switch-mode2-command = [
					39 00 00 40 00 00 04 FF 5A A5 00
					15 00 00 40 00 00 02 60 00
					39 00 00 40 00 00 04 FF 5A A5 2D
					39 00 00 40 00 00 03 83 01 00
					15 00 00 40 00 00 02 F2 01
					39 00 00 40 00 00 04 FF 5A A5 23
					15 00 00 40 00 00 02 CA 04
					15 00 00 40 00 00 02 CE 01
					39 00 00 40 00 00 04 FF 5A A5 24
					15 00 00 40 00 00 02 8D 01
					15 00 00 40 00 00 02 8E 30
					15 00 00 40 00 00 02 8F 21
					15 00 00 40 00 00 02 90 30
					39 00 00 40 00 00 04 FF 5A A5 01
					39 00 00 40 00 00 07 80 0C 00 00 00 10 27
					39 00 00 40 00 00 04 FF 5A A5 0A
					39 00 00 40 00 00 05 D8 00 07 29 80
					39 00 00 40 00 00 04 FF 5A A5 0B
					39 00 00 40 00 00 04 E9 00 00 21
					39 00 00 40 00 00 04 FF 5A A5 51
					39 00 00 40 00 00 07 A0 CB CB CB CB 22 22
					39 00 00 40 00 00 07 A1 CB CB CB CB 22 22
					39 00 00 40 00 00 07 A2 CB CB CB CB 22 22
					39 00 00 40 00 00 07 A3 CB CB CB CB 22 22
					39 00 00 40 00 00 07 A4 CB CB CB CB 22 22
					39 00 00 40 00 00 07 A5 CB CB CB C7 22 22
					39 00 00 40 00 00 07 A6 C7 C3 C3 C3 22 22
					39 00 00 40 00 00 07 A7 C3 C3 00 00 22 00
					39 00 00 40 00 00 04 FF 5A A5 52
					39 00 00 40 00 00 07 80 2D 79 74 74 01 00
					39 00 00 40 00 00 07 81 6F 6F 6A 6A 00 00
					39 00 00 40 00 00 07 82 65 65 60 60 00 00
					39 00 00 40 00 00 07 83 5B 5B 56 56 00 00
					39 00 00 40 00 00 07 84 51 51 4C 4C 00 00
					39 00 00 00 00 00 07 85 47 47 47 46 00 00
				];
				qcom,mdss-dsi-timming-switch-pwm-mode2-command = [
					/* 90Hz DC */
					39 00 00 40 00 00 04 FF 5A A5 00
					15 00 00 40 00 00 02 60 03
					39 00 00 40 00 00 04 FF 5A A5 2D
					39 00 00 40 00 00 03 86 00 00
					15 00 00 40 00 00 02 F2 00
					39 00 00 00 00 00 04 FF 5A A5 00
				];
				qcom,mdss-dsi-pwm-switch-mode2-panel-on-command = [
					39 00 00 40 00 00 04 FF 5A A5 00
					15 00 00 40 00 00 02 60 00
					39 00 00 40 00 00 04 FF 5A A5 2D
					39 00 00 40 00 00 03 83 01 00
					15 00 00 40 00 00 02 F2 01
					39 00 00 40 00 00 04 FF 5A A5 23
					15 00 00 40 00 00 02 CA 04
					15 00 00 40 00 00 02 CE 01
					39 00 00 40 00 00 04 FF 5A A5 24
					15 00 00 40 00 00 02 8D 01
					15 00 00 40 00 00 02 8E 30
					15 00 00 40 00 00 02 8F 21
					15 00 00 40 00 00 02 90 30
					39 00 00 40 00 00 04 FF 5A A5 01
					39 00 00 40 00 00 07 80 0C 00 00 00 10 27
					39 00 00 40 00 00 04 FF 5A A5 0A
					39 00 00 40 00 00 05 D8 00 07 29 80
					39 00 00 40 00 00 04 FF 5A A5 0B
					39 00 00 40 00 00 04 E9 00 00 21
					39 00 00 40 00 00 04 FF 5A A5 51
					39 00 00 40 00 00 07 A0 CB CB CB CB 22 22
					39 00 00 40 00 00 07 A1 CB CB CB CB 22 22
					39 00 00 40 00 00 07 A2 CB CB CB CB 22 22
					39 00 00 40 00 00 07 A3 CB CB CB CB 22 22
					39 00 00 40 00 00 07 A4 CB CB CB CB 22 22
					39 00 00 40 00 00 07 A5 CB CB CB C7 22 22
					39 00 00 40 00 00 07 A6 C7 C3 C3 C3 22 22
					39 00 00 40 00 00 07 A7 C3 C3 00 00 22 00
					39 00 00 40 00 00 04 FF 5A A5 52
					39 00 00 40 00 00 07 80 2D 79 74 74 01 00
					39 00 00 40 00 00 07 81 6F 6F 6A 6A 00 00
					39 00 00 40 00 00 07 82 65 65 60 60 00 00
					39 00 00 40 00 00 07 83 5B 5B 56 56 00 00
					39 00 00 40 00 00 07 84 51 51 4C 4C 00 00
					39 00 00 00 00 00 07 85 47 47 47 46 00 00
				];
			};
			timing@sdc_fhd_144 {
				#include "dsi-panel-AE084-P-7-A0020-common.dtsi"
				qcom,mdss-mdp-transfer-time-us = <6100>;
				qcom,mdss-dsi-panel-jitter = <0x4 0x1>;
				qcom,mdss-dsc-version = <0x12>;
				qcom,mdss-dsi-timing-default;
				qcom,mdss-dsi-panel-framerate = <144>;
				qcom,mdss-dsi-panel-clockrate = <1363200000>;
				qcom,mdss-dsi-panel-width = <1272>;
				qcom,mdss-dsi-panel-height = <2772>;

				qcom,mdss-dsi-h-front-porch = <16>;
				qcom,mdss-dsi-h-back-porch = <16>;
				qcom,mdss-dsi-h-pulse-width = <2>;
				qcom,mdss-dsi-v-back-porch = <28>;
				qcom,mdss-dsi-v-front-porch = <78>;
				qcom,mdss-dsi-v-pulse-width = <2>;
				qcom,mdss-dsi-h-sync-pulse = <0>;

				oplus,ofp-need-to-sync-data-in-aod-unlocking;
				oplus,ofp-aod-off-insert-black-frame = <1>;
				oplus,ofp-aod-off-black-frame-total-time = <42>;
				oplus,ofp-need-to-separate-backlight;
				oplus,ofp-backlight-on-period = <1>;

				qcom,mdss-dsi-timing-switch-command = [
					39 00 00 40 00 00 04 FF 5A A5 00
					15 00 00 40 00 00 02 60 04 //144hz 3 pulse
					39 00 00 40 00 00 04 FF 5A A5 2D
					39 00 00 40 00 00 03 87 00 00
					39 00 00 00 00 00 04 FF 5A A5 00
				];
				qcom,mdss-dsi-on-command = [
					39 00 00 40 00 00 04 FF 5A A5 20
					15 00 00 40 00 00 02 C8 00
					15 00 00 40 00 00 02 C7 00
					15 00 00 40 00 00 02 BF 17
					39 00 00 40 00 00 04 FF 5A A5 00
					39 00 00 40 00 00 05 94 00 D0 00 00
					39 00 00 40 00 00 04 FF 5A A5 1F
					39 00 00 40 00 00 03 82 00 20
					15 00 00 40 00 00 02 87 09
					15 00 00 40 00 00 02 88 34
					39 00 00 40 00 00 05 89 41 00 C4 01
					39 00 00 40 00 00 03 8A 8C 14
					39 00 00 40 00 00 05 8C 80 07 00 40
					15 00 00 40 00 00 02 8E 10
					15 00 00 40 00 00 02 95 00
					39 00 00 40 00 00 05 96 15 35 55 00
					39 00 00 40 00 00 06 97 11 33 22 01 09
					39 00 00 40 00 00 19 83 00 0B 0A 0C 02 FF FF FF 0C 02 FF FF 00 FF 00 0B 00 FF FF FF FF FF FF FF
					39 00 00 40 00 00 19 8F 03 2C 8C 19 07 00 00 00 19 07 00 00 00 00 02 2C 02 00 00 00 00 00 00 00
					39 00 00 40 00 00 09 85 00 0B 0A FF FF FF FF FF
					39 00 00 40 00 00 09 91 03 2C 24 00 00 00 00 00
					39 00 00 40 00 00 04 FF 5A A5 29
					39 00 00 40 00 00 09 82 78 30 2E 2E 2C 2C 2A 2A
					39 00 00 40 00 00 09 83 28 28 26 26 24 24 22 22
					39 00 00 40 00 00 09 84 20 20 1E 1E 1C 1C 18 18
					39 00 00 40 00 00 07 85 18 18 18 18 18 18
					39 00 00 40 00 00 04 FF 5A A5 00

					39 00 00 40 00 00 04 FF 5A A5 08
					15 00 00 40 00 00 02 C8 62
					39 00 00 40 00 00 04 FF 5A A5 07
					15 00 00 40 00 00 02 8A 01
					39 00 00 40 00 00 03 8B 21 E0 // PPS Table
					39 00 00 40 00 00 64 81 00 00 00 00 00 12 00 00 AB 30 80 0A D4 04 F8 00 16 02 7C 02 7C 02 00 02 59 00 20 02 2E 00 08 00 0D 04 F4 03 ED 18 00 10 F0 07 10 20 00 06 0F 0F 33 0E 1C 2A 38 46 54 62 69 70 77 79 7B 7D 7E 02 02 22 00 2A 40 2A BE 3A FC 3A FA 3A F8 3B 38 3B 78 3B B6 4B B6 4B F4 4B F4 6C 34 84 74 00 00 00 00 00 00
					39 00 00 40 00 00 04 FF 5A A5 00

					39 00 00 40 00 00 04 FF 5A A5 21
					15 00 00 40 00 00 02 A4 18 // Flash reload
					39 00 00 40 00 00 04 FF 5A A5 01
					15 00 00 40 00 00 02 FB 08 // Multi TE
					39 00 00 40 00 00 04 FF 5A A5 06
					15 00 00 40 00 00 02 A0 00 // ESD fixed
					15 00 00 40 00 00 02 C6 01 // 1 bit ESD check
					39 00 00 40 00 00 04 FF 5A A5 08
					15 00 00 40 00 00 02 D2 05
					15 00 00 40 00 00 02 D3 01
					39 00 00 40 00 00 09 ED FF FF FF F7 FF CF 45 FF
					39 00 00 40 00 00 09 EE FF FD C1 F8 21 00 80 50
					39 00 00 40 00 00 04 FF 5A A5 2F
					15 00 00 40 00 00 02 99 80
					39 00 00 40 00 00 04 FF 5A A5 1F
					15 00 00 40 00 00 02 B2 F0
					39 00 00 40 00 00 04 FF 5A A5 6E
					39 00 00 40 00 00 05 C8 66 C4 66 D9
					39 00 00 40 00 00 05 C9 66 A8 66 B3
					39 00 00 40 00 00 05 CA 67 66 66 BB
					39 00 00 40 00 00 05 CB 66 82 66 8D
					39 00 00 40 00 00 05 CC 66 95 67 6F
					39 00 00 40 00 00 05 CD 67 76 67 71
					39 00 00 40 00 00 05 CE 67 4B 67 5A
					39 00 00 40 00 00 05 CF 67 3F 67 0E
					39 00 00 40 00 00 05 D0 67 7B 67 7F
					39 00 00 40 00 00 05 D1 67 76 67 6A
					39 00 00 40 00 00 05 D2 67 66 67 61
					39 00 00 40 00 00 05 D3 67 65 66 90
					39 00 00 40 00 00 05 D4 66 97 66 8B
					39 00 00 40 00 00 05 D5 66 82 66 86
					39 00 00 40 00 00 05 D6 66 BD 66 B1
					39 00 00 40 00 00 05 D7 66 A8 66 AC
					39 00 00 40 00 00 04 FF 5A A5 6B
					39 00 00 40 00 00 05 9B 0C DF 21 F5
					39 00 00 40 00 00 05 9C 58 D8 23 A4
					39 00 00 40 00 00 05 9D 6E E1 21 E7
					39 00 00 40 00 00 05 9E 77 04 2C C2
					39 00 00 40 00 00 05 9F E1 51 1A EA
					39 00 00 40 00 00 05 A0 A4 33 28 29
					39 00 00 40 00 00 05 BF 0C DF 21 F5
					39 00 00 40 00 00 05 C0 58 D8 23 A4
					39 00 00 40 00 00 05 C1 6E E1 21 E7
					39 00 00 40 00 00 05 C2 77 04 2C C2
					39 00 00 40 00 00 05 C3 E1 51 1A EA
					39 00 00 40 00 00 05 C4 A4 33 28 29
					39 00 00 40 00 00 04 FF 5A A5 6C
					39 00 00 40 00 00 05 B3 0D DC 22 DE
					39 00 00 40 00 00 05 B4 48 D9 23 B4
					39 00 00 40 00 00 05 B5 5E EE 2C C0
					39 00 00 40 00 00 05 B6 26 14 2F E9
					39 00 00 40 00 00 05 B7 B2 31 1C ED
					39 00 00 40 00 00 05 B8 E5 50 2F 4B
					39 00 00 40 00 00 05 D7 0D DC 22 DE
					39 00 00 40 00 00 05 D8 48 D9 23 B4
					39 00 00 40 00 00 05 D9 5E EE 2C C0
					39 00 00 40 00 00 05 DA 26 14 2F E9
					39 00 00 40 00 00 05 DB B2 31 1C ED
					39 00 00 40 00 00 05 DC E5 50 2F 4B
					39 00 00 40 00 00 04 FF 5A A5 2F
					15 00 00 40 00 00 02 99 00
					39 00 00 40 00 00 04 FF 5A A5 00
					15 00 00 40 00 00 02 5E 01
					15 00 00 40 00 00 02 60 00
					15 00 00 40 00 00 02 61 07
					15 00 00 40 00 00 02 6D 01
					15 00 00 40 00 00 02 35 00
					15 00 00 40 00 00 02 53 20
					39 00 00 40 00 00 05 51 07 4D 03 DD // p1 p2 normal DBV p3 p4 AOD DBV
					/* 144hz 3 pulse */
					39 00 00 40 00 00 04 FF 5A A5 00
					15 00 00 40 00 00 02 60 04 //144hz 3 pulse
					39 00 00 40 00 00 04 FF 5A A5 2D
					39 00 00 40 00 00 03 87 00 00
					39 00 00 00 00 00 04 FF 5A A5 00
					//Light On
					15 00 00 00 78 00 02 11 00
					15 00 00 00 14 00 02 29 00
				];
				/* PWM */
				qcom,mdss-dsi-pwm-switch-mode0-command = [
					39 00 00 40 00 00 04 FF 5A A5 00
					15 00 00 40 00 00 02 60 01
					39 00 00 40 00 00 04 FF 5A A5 2D
					15 00 00 40 00 00 02 F2 00
					39 00 00 40 00 00 04 FF 5A A5 23
					15 00 00 40 00 00 02 CA 00
					15 00 00 40 00 00 02 CE 00
					39 00 00 40 00 00 04 FF 5A A5 24
					15 00 00 40 00 00 02 8D 02
					15 00 00 40 00 00 02 8E 60
					15 00 00 40 00 00 02 8F 43
					15 00 00 40 00 00 02 90 70
					39 00 00 40 00 00 04 FF 5A A5 01
					39 00 00 40 00 00 07 80 0C 00 00 00 10 33
					39 00 00 40 00 00 04 FF 5A A5 0A
					39 00 00 40 00 00 05 D8 00 07 35 80
					39 00 00 40 00 00 04 FF 5A A5 0B
					39 00 00 40 00 00 04 E9 00 00 2D
					39 00 00 40 00 00 04 FF 5A A5 51
					39 00 00 40 00 00 07 A0 CA CA CA CA 22 22
					39 00 00 40 00 00 07 A1 CA CA CA CA 22 22
					39 00 00 40 00 00 07 A2 CA CA CA CA 22 22
					39 00 00 40 00 00 07 A3 CA CA CA CA 22 22
					39 00 00 40 00 00 07 A4 CA CA CA CA 22 22
					39 00 00 40 00 00 07 A5 CA CA CA CA 22 22
					39 00 00 40 00 00 07 A6 CA CA CA CA 22 22
					39 00 00 40 00 00 07 A7 CA CA 00 00 22 00
					39 00 00 40 00 00 04 FF 5A A5 52
					39 00 00 40 00 00 07 80 2C 78 73 73 01 00
					39 00 00 40 00 00 07 81 6E 6E 69 69 00 00
					39 00 00 40 00 00 07 82 64 64 5F 5F 00 00
					39 00 00 40 00 00 07 83 5A 5A 55 55 00 00
					39 00 00 40 00 00 07 84 50 50 4B 4B 00 00
					39 00 00 00 00 00 07 85 46 46 46 46 00 00
				];
				qcom,mdss-dsi-pwm-switch-mode2-command = [
					39 00 00 40 00 00 04 FF 5A A5 00
					15 00 00 40 00 00 02 60 00
					39 00 00 40 00 00 04 FF 5A A5 2D
					15 00 00 40 00 00 02 F2 00
					39 00 00 40 00 00 04 FF 5A A5 23
					15 00 00 40 00 00 02 CA 04
					15 00 00 40 00 00 02 CE 01
					39 00 00 40 00 00 04 FF 5A A5 24
					15 00 00 40 00 00 02 8D 01
					15 00 00 40 00 00 02 8E 30
					15 00 00 40 00 00 02 8F 21
					15 00 00 40 00 00 02 90 30
					39 00 00 40 00 00 04 FF 5A A5 01
					39 00 00 40 00 00 07 80 0C 00 00 00 10 27
					39 00 00 40 00 00 04 FF 5A A5 0A
					39 00 00 40 00 00 05 D8 00 07 29 80
					39 00 00 40 00 00 04 FF 5A A5 0B
					39 00 00 40 00 00 04 E9 00 00 21
					39 00 00 40 00 00 04 FF 5A A5 51
					39 00 00 40 00 00 07 A0 CB CB CB CB 22 22
					39 00 00 40 00 00 07 A1 CB CB CB CB 22 22
					39 00 00 40 00 00 07 A2 CB CB CB CB 22 22
					39 00 00 40 00 00 07 A3 CB CB CB CB 22 22
					39 00 00 40 00 00 07 A4 CB CB CB CB 22 22
					39 00 00 40 00 00 07 A5 CB CB CB C7 22 22
					39 00 00 40 00 00 07 A6 C7 C3 C3 C3 22 22
					39 00 00 40 00 00 07 A7 C3 C3 00 00 22 00
					39 00 00 40 00 00 04 FF 5A A5 52
					39 00 00 40 00 00 07 80 2D 79 74 74 01 00
					39 00 00 40 00 00 07 81 6F 6F 6A 6A 00 00
					39 00 00 40 00 00 07 82 65 65 60 60 00 00
					39 00 00 40 00 00 07 83 5B 5B 56 56 00 00
					39 00 00 40 00 00 07 84 51 51 4C 4C 00 00
					39 00 00 40 00 00 07 85 47 47 47 46 00 00
					39 00 00 00 00 00 07 86 46 46 46 46 00 00
				];
				qcom,mdss-dsi-timming-switch-pwm-mode2-command = [
					39 00 00 40 00 00 04 FF 5A A5 00
					15 00 00 40 00 00 02 60 01
					39 00 00 40 00 00 04 FF 5A A5 2D
					39 00 00 40 00 00 03 84 00 00
					15 00 00 40 00 00 02 F2 00
					39 00 00 00 00 00 04 FF 5A A5 00
				];
				qcom,mdss-dsi-pwm-switch-mode2-panel-on-command = [
					39 00 00 40 00 00 04 FF 5A A5 00
					15 00 00 40 00 00 02 60 00
					39 00 00 40 00 00 04 FF 5A A5 2D
					15 00 00 40 00 00 02 F2 00
					39 00 00 40 00 00 04 FF 5A A5 23
					15 00 00 40 00 00 02 CA 04
					15 00 00 40 00 00 02 CE 01
					39 00 00 40 00 00 04 FF 5A A5 24
					15 00 00 40 00 00 02 8D 01
					15 00 00 40 00 00 02 8E 30
					15 00 00 40 00 00 02 8F 21
					15 00 00 40 00 00 02 90 30
					39 00 00 40 00 00 04 FF 5A A5 01
					39 00 00 40 00 00 07 80 0C 00 00 00 10 27
					39 00 00 40 00 00 04 FF 5A A5 0A
					39 00 00 40 00 00 05 D8 00 07 29 80
					39 00 00 40 00 00 04 FF 5A A5 0B
					39 00 00 40 00 00 04 E9 00 00 21
					39 00 00 40 00 00 04 FF 5A A5 51
					39 00 00 40 00 00 07 A0 CB CB CB CB 22 22
					39 00 00 40 00 00 07 A1 CB CB CB CB 22 22
					39 00 00 40 00 00 07 A2 CB CB CB CB 22 22
					39 00 00 40 00 00 07 A3 CB CB CB CB 22 22
					39 00 00 40 00 00 07 A4 CB CB CB CB 22 22
					39 00 00 40 00 00 07 A5 CB CB CB C7 22 22
					39 00 00 40 00 00 07 A6 C7 C3 C3 C3 22 22
					39 00 00 40 00 00 07 A7 C3 C3 00 00 22 00
					39 00 00 40 00 00 04 FF 5A A5 52
					39 00 00 40 00 00 07 80 2D 79 74 74 01 00
					39 00 00 40 00 00 07 81 6F 6F 6A 6A 00 00
					39 00 00 40 00 00 07 82 65 65 60 60 00 00
					39 00 00 40 00 00 07 83 5B 5B 56 56 00 00
					39 00 00 40 00 00 07 84 51 51 4C 4C 00 00
					39 00 00 40 00 00 07 85 47 47 47 46 00 00
					39 00 00 00 00 00 07 86 46 46 46 46 00 00
				];
			};
		};
	};
};

&soc {
	dsi_panel_AE084_P_7_A0020_dsc_cmd {
		qcom,dsi-display-active;
	};
};

&dsi_panel_AE084_P_7_A0020_dsc_cmd {
	qcom,panel-supply-entries = <&oplus_dsi_panel_custom_pwr_supply>;
	qcom,platform-te-gpio = <&tlmm 86 0>;
	qcom,platform-reset-gpio = <&tlmm 171 0>;
	/* OLED_PMIC_RST */
	oplus,panel-gpio1 = <&pmk8850_gpios 1 0>;
	/* VDDR_SM_1P5_EN */
	oplus,panel-gpio2 = <&pmh0101_gpios 4 0>;

    oplus,panel-reset-position = <0x02>;
	oplus,panel-power-on-sequence = "1", "vddio", "3", "vdd","3", "gpio1", "3", "gpio2", "3", "vci", "10";
	oplus,panel-power-off-sequence = "1", "vci", "3", "gpio2", "3", "gpio1", "3", "vdd", "3", "vddio", "1";

    //enable mipi strength
	oplus,enhance_mipi_strength;

    /* BRIGHTNESS CONFIG */
    qcom,mdss-dsi-bl-pmic-control-type = "bl_ctrl_dcs";
	qcom,bl-update-flag = "delay_until_first_frame";
    qcom,mdss-dsi-bl-inverted-dbv;
    qcom,mdss-dsi-bl-min-level = <1>;
	qcom,mdss-dsi-bl-max-level = <4094>;
	qcom,mdss-brightness-max-level = <4094>;
	oplus,dsi-bl-normal-max-level = <3515>;
	oplus,dsi-brightness-normal-max-level = <3515>;
	oplus,dsi-dc-backlight-threshold = <1960>;
	oplus,dsi-brightness-default-level = <1638>;

    /* ESD CONFIG */
    qcom,esd-check-enabled;
    oplus,esd-check-flag-enabled;
    qcom,mdss-dsi-panel-status-check-mode = "reg_read";
    qcom,mdss-dsi-panel-status-command = [
            06 00 00 00 00 00 01 0A
    ];
    qcom,mdss-dsi-panel-status-command-state = "dsi_lp_mode";
    qcom,mdss-dsi-panel-status-value = <
            0x9C
    >;
    qcom,mdss-dsi-panel-status-read-length = <1>;
    oplus,mdss-dsi-panel-status-match-modes = <0x00000000>;

    /* FACTORY CONFIG */
    oplus,mdss-dsi-vendor-name = "A0020";
    oplus,mdss-dsi-manufacture = "P_7";
	oplus,color_vivid_status;
	oplus,color_srgb_status;
	oplus,color_softiris_status;
	//oplus,color_oplus_calibrate_status;
	oplus,color_dual_brightness_status;
	oplus,color_2nit_status;
	oplus,color_loading_status;
	oplus,color_nature_profession_status;
	oplus,mdss-dsi-panel-type = <0>;

    /* OPLUS FEATURES CONFIG */
	oplus,dsi-serial-number-enabled;
	oplus,dsi-serial-number-switch-page;
	oplus,dsi-serial-number-index= <0>;
	oplus,dsi-serial-number-reg= <0x80>;
	oplus,dsi-serial-number-read-count= <7>;
	qcom,ulps-enabled;
	qcom,dsi-select-clocks = "pll_byte_clk0", "pll_dsi_clk0";

	oplus,vreg_ctrl_flag;

	/* ofp config */
	oplus,ofp-fp-type = <0x40>;
	oplus,ofp-longrui-aod-config = <0x02>;
	oplus,ofp-need-to-wait-data-before-aod-on;
	oplus,ofp-aod-off-frame-cost = <1>;
	/* adfr config */
	//oplus,adfr-config = <0xe51>;  // 0b0000'0000'0101'0001
	//oplus,adfr-test-te-gpio = <&tlmm 85 0>;
	/* just for qsync enable*/
	//qcom,qsync-enable;
	//qcom,mdss-dsi-qsync-min-refresh-rate = <30>;

	// qcom,dsi-dyn-clk-enable;

	qcom,mdss-dsi-display-timings {
		timing@sdc_fhd_120 { /* FHD+ 120hz 1112.6Mbps */
			qcom,mdss-dsi-panel-phy-timings = [00 24 0A 0A 1A 18 0A 0A 09 02 04 00 1E 0F];
			qcom,display-topology = <1 1 1>,<2 2 1>;
			qcom,default-topology-index = <1>;
			//qcom,partial-update-enabled = "single_roi";
			//qcom,panel-roi-alignment = <1264 60 1264 60 1264 60>;
			qcom,dsi-mode-te-width-us = <315>;
		};
		timing@sdc_fhd_90 { /* FHD+ 90hz 1112.6Mbps */
			qcom,mdss-dsi-panel-phy-timings = [00 24 0A 0A 1A 18 0A 0A 09 02 04 00 1E 0F];
			qcom,display-topology = <1 1 1>,<2 2 1>;
			qcom,default-topology-index = <1>;
			//qcom,partial-update-enabled = "single_roi";
			//qcom,panel-roi-alignment = <1264 60 1264 60 1264 60>;
			qcom,dsi-mode-te-width-us = <315>;
		};
		timing@sdc_fhd_60 { /* FHD+ 60hz 1112.6Mbps */
			qcom,mdss-dsi-panel-phy-timings = [00 24 0A 0A 1A 18 0A 0A 09 02 04 00 1E 0F];
			qcom,display-topology = <1 1 1>,<2 2 1>;
			qcom,default-topology-index = <1>;
			//qcom,partial-update-enabled = "single_roi";
			//qcom,panel-roi-alignment = <1264 60 1264 60 1264 60>;
			qcom,dsi-mode-te-width-us = <315>;
		};
		timing@sdc_fhd_144 { /* FHD+ 144hz 1363.2Mbps */
			qcom,mdss-dsi-panel-phy-timings = [00 2C 0C 0C 1D 1A 0C 0C 0B 02 04 00 24 11];
			qcom,display-topology = <1 1 1>,<2 2 1>;
			qcom,default-topology-index = <1>;
			//qcom,partial-update-enabled = "single_roi";
			//qcom,panel-roi-alignment = <1264 60 1264 60 1264 60>;
			qcom,dsi-mode-te-width-us = <315>;
		};
	};
};

&dsi_panel_AE084_P_7_A0020_dsc_cmd {
	qcom,panel_voltage_vddi_name = "vddio";
	qcom,panel_voltage_vddi = <0 1800000 1850000 1950000>;
	qcom,panel_voltage_vddr_name = "vddio";
	qcom,panel_voltage_vddr = <1 1800000 1850000 1950000>;
};

&dsi_panel_AE084_P_7_A0020_dsc_cmd{
	/* demura dbv config */

	/* pwm config */
	/*	oplus,pwm-switch-config:
		Bit0: pwm feature enable
		Bit1: pwm mode switch enable, need to config switch cmds
		Bit2: force enabled pwm mode switch cmd, will send mode cmd even dbv threshold cmd feature is configed
		Bit3: pwm dbv threshold pulse switch enable, need to config threshold switch cmds
		Bit4: wait te before sending pwm dbv threshold pulse switch cmd
		Bit5: replace specific cmd to other cmd while in pwm 1pulse mode
		Bit6: sending extend cmd while panel power on accroding to current pwm mode
		Bit7: sending extend cmd while timing switch accroding to current pwm pulse level
		Bit8: sending extend cmd after sending dbv threshold cmd in another thread
		...
		Bit24:support pwm mode0
		Bit25:support pwm mode1
		Bit25:support pwm mode2
	*/
	oplus,pwm-switch-config = <0x05000067>;
	/*	oplus,pwm-switch-mode0-states-info/oplus,pwm-switch-mode1-states-info:
		Specific dbv threshold and pulse info of 2 pwm mode, for pulse, 0 symbols 1pulse,
		1symbols 3pulse and 2 symbols 18pulse. The format should be 1 dbv threshold info with
		2 pwm pulse levels left and right(for example, <2 1087 1> means 18pulse while dbv <= 1087
		and 3pulse while dbv > 1087), or only one pulse level, no threshold.
	*/
	oplus,pwm-switch-mode0-states-info = <2 1162 1>;
	oplus,pwm-switch-mode2-states-info = <0>;
	/*	oplus,pwm-cmd-switch-map:
		Specific cmd replace relationship while in switch on(1pulse) mode. It is a string array that
		compose with cmd names, every 2 names combine 1 map. For example, map "'a', 'b'" means replace
		a to b while sending a in switch on mode.
	*/
	oplus,pwm-cmd-switch-map = "qcom,mdss-dsi-nolp-command", "qcom,mdss-dsi-aod-off-pwm-mode2-command",
			"qcom,mdss-dsi-timing-switch-command", "qcom,mdss-dsi-timming-switch-pwm-mode2-command";
};
